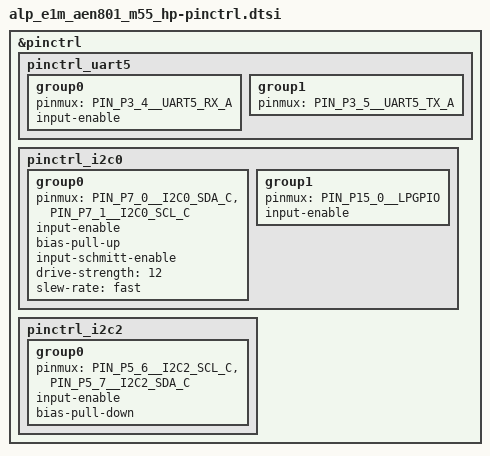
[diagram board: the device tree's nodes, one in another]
/*
 * Copyright (c) 2026 Alp Lab AB
 * SPDX-License-Identifier: Apache-2.0
 * Auto-generated by `scripts/alp_project.py --emit zephyr-board` from
 * metadata/e1m_modules/E1M-AEN801.yaml + metadata/socs/alif/ensemble/e8.json + metadata/e1m_modules/aen/on-module-links.yaml.
 * DO NOT EDIT BY HAND -- regenerate.
 *
 * E1M-AEN801 (Alif Ensemble E8) Cortex-M55-HP carrier pin control.
 *
 * Console: the E1M edge "UART0" maps to Alif UART5 (P3_4 RX_A / P3_5 TX_A) on
 * the AEN module PCB; the Alp E1M-EVK carrier wires its USB-UART console to it.
 * (In an HE+HP AMP image the two cores share this single physical console;
 * during bring-up each core is flashed/run independently.)  Confirmed against
 * the SoM netlist + metadata/e1m_modules/aen/from-alif.tsv.
 *
 *
 * BRD_I2C (SoC I2C0, function C) is wired here too: it is an ON-MODULE bus
 * carrying SoM-resident parts (RTC + temperature sensor), present on every
 * board built from this SoM -- not a per-app choice, so it belongs in the
 * board layer rather than in each consumer's overlay.  Pads, macros and pad
 * config come from metadata/e1m_modules/aen/on-module-links.yaml.
 *
 * SoC I2C2 (function C, portable alp-i2c0) is wired here too, for the same
 * reason: the SoM's own 24C128 manifest EEPROM is bridge/DNP-selected onto
 * it, so every board built from this SoM needs the controller enabled --
 * even though the same pads also carry the EVK carrier's sensor bus once
 * they leave the module (docs/bring-up-aen.md Sec 5.1).
 *
 * Remaining GPIO / SPI / Ethernet pin groups are added alongside their
 * drivers (the alp-sdk Alif peripheral drivers).
 */

#include <zephyr/dt-bindings/pinctrl/alif-ensemble-pinctrl.h>

&pinctrl {
	pinctrl_uart5: pinctrl_uart5 {
		group0 {
			pinmux = <PIN_P3_4__UART5_RX_A>;
			input-enable;
		};

		group1 {
			pinmux = <PIN_P3_5__UART5_TX_A>;
		};
	};

	/*
	 * BRD_I2C = SoC I2C0 function C: P7_0 SDA / P7_1 SCL,
	 * the on-module housekeeping bus (see the board .dts for the parts on it).
	 *
	 * BOTH pins get input-enable, in one group -- Alif's own DFP sets
	 * PADCTRL_READ_ENABLE on P7_0 AND P7_1.  With it on SDA only, the
	 * i2c_dw controller cannot SENSE SCL (clock-stretch detect / arbitration)
	 * and NACKs every address for a reason that looks electrical but is not.
	 *
	 * bias-pull-up is DSC=1, a REAL pull-up: pinctrl_soc.h's field comment
	 * (soc/alif/ensemble/pinctrl_soc.h:24) and its ALIF_PINCTRL_BIAS_CFG()
	 * macro (:44-48) both map bias-pull-up -> DSC=1 unconditionally -- there
	 * is NO inversion between the devicetree property and the DSC field, on
	 * this bus or the e1m_i2c0 one below (#2046 corrected that group's
	 * comment, which used to claim the opposite).  Do NOT copy the
	 * I2C2/EEPROM overlay's bias-pull-down: DSC=2 is a pull-DOWN, harmless
	 * there only because that bus has external carrier pull-ups (R137/R144).
	 * This net has NO external pull-up at all, so a pull-down would park both
	 * lines low and look like a busy bus.
	 *
	 * drive-open-drain is deliberately NOT set, so bit 23 [DRV] stays 0 =
	 * PUSH-PULL: the pad actively drives the high phase instead of relying on
	 * a pull-up this net does not have.  input-schmitt-enable + max
	 * drive-strength/slew-rate cover the resulting slow edges.  Bench-proven
	 * 2026-09-05 on E1M-AEN801 2626-R2: every non-response is a clean rc=-5
	 * (-EIO) NACK, zero -ETIMEDOUT, zero "User Abort".
	 */
	pinctrl_i2c0: pinctrl_i2c0 {
		group0 {
			pinmux = <PIN_P7_0__I2C0_SDA_C>, <PIN_P7_1__I2C0_SCL_C>;
			input-enable;
			bias-pull-up;
			input-schmitt-enable;
			drive-strength = <12>;
			slew-rate = "fast";
		};

		/*
		 * RTC_ALARM: the RV-3028 /INT line on P15_0 (lpgpio bit 0).
		 * Muxed + input-enabled here because snps,designware-gpio has no
		 * pinctrl-0 of its own (see this function's docstring); without it the
		 * pad input buffer stays off and the alarm reads 0 forever.
		 */
		group1 {
			pinmux = <PIN_P15_0__LPGPIO>;
			input-enable;
		};
	};

	/*
	 * e1m_i2c0 = SoC I2C2 function C: P5_7 SDA / P5_6 SCL,
	 * portable alp-i2c0 (E1M edge bus 0 -- ALP_E1M_I2C0 /
	 * EVK_I2C_BUS_SENSORS).  Carries the SoM's own 24C128 manifest EEPROM;
	 * the same pads also reach the EVK carrier's sensor bus once they leave
	 * the module (docs/bring-up-aen.md Sec 5.1 -- two separate buses).
	 *
	 * input-enable + bias-pull-down: bench-validated 2026-06-15 on the E8,
	 * matching Alif's own reference I2C pinctrl -- see the identical, verbatim-
	 * copied group in examples/aen/aen-i2c2-eeprom-regcheck's board overlay and
	 * examples/aen/aen-eeprom-manifest's overlay, both of which cite the same
	 * date.
	 *
	 * bias-pull-down really is a pull-down (DSC=2), and bias-pull-up really
	 * would be a pull-up (DSC=1) -- pinctrl_soc.h does NOT invert the two.
	 * Its ALIF_PINCTRL_BIAS_CFG() macro (soc/alif/ensemble/pinctrl_soc.h:44-48)
	 * maps bias-pull-up -> DSC=1 and bias-pull-down -> DSC=2 unconditionally,
	 * exactly as the field's own comment at :24 describes.  An earlier version
	 * of this comment (and of examples/aen/aen-eeprom-manifest's overlay) blamed
	 * bias-pull-up's reported dead bus on that encoding "reading inverted vs
	 * the Alif pad hardware" -- pinctrl_soc.h has no such inversion, so that
	 * explanation is RETRACTED (#2046), and the dead-bus report it was invented
	 * to explain is UNCONFIRMED, not disproven: nobody has re-run bias-pull-up
	 * here in a controlled bench trial since.  What IS established, matching
	 * the BRD_I2C group's own reasoning above: this bus, unlike BRD_I2C, has
	 * the EVK carrier's R137/R144 pull-ups stuffed, so a real internal
	 * pull-down is harmless -- the strong external pull-up dominates a weak
	 * internal one -- which is why bias-pull-down is bench-proven correct as
	 * emitted.  Do NOT change it to bias-pull-up on the strength of either
	 * reading; that needs a fresh register-level bench comparison, not a theory.
	 */
	pinctrl_i2c2: pinctrl_i2c2 {
		group0 {
			pinmux = <PIN_P5_6__I2C2_SCL_C>, <PIN_P5_7__I2C2_SDA_C>;
			input-enable;
			bias-pull-down;
		};
	};
};
